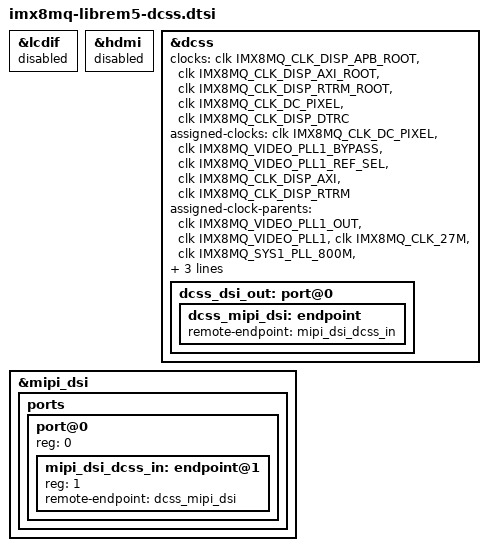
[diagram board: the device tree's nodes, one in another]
// SPDX-License-Identifier: GPL-2.0+
/*
 * Copyright 2021 Purism SPC
 */

/delete-node/ &mipi_dsi_lcdif_in;
/delete-node/ &lcdif_mipi_dsi;

&lcdif {
	status = "disabled";
};

&hdmi {
	status = "disabled";
};

&dcss {
	status = "okay";

	clocks = <&clk IMX8MQ_CLK_DISP_APB_ROOT>,
		 <&clk IMX8MQ_CLK_DISP_AXI_ROOT>,
		 <&clk IMX8MQ_CLK_DISP_RTRM_ROOT>,
		 <&clk IMX8MQ_CLK_DC_PIXEL>,
		 <&clk IMX8MQ_CLK_DISP_DTRC>;
	clock-names = "apb", "axi", "rtrm", "pix", "dtrc";
	assigned-clocks = <&clk IMX8MQ_CLK_DC_PIXEL>,
					  <&clk IMX8MQ_VIDEO_PLL1_BYPASS>,
					  <&clk IMX8MQ_VIDEO_PLL1_REF_SEL>,
					  <&clk IMX8MQ_CLK_DISP_AXI>,
					  <&clk IMX8MQ_CLK_DISP_RTRM>;
	assigned-clock-parents = <&clk IMX8MQ_VIDEO_PLL1_OUT>,
							 <&clk IMX8MQ_VIDEO_PLL1>,
							 <&clk IMX8MQ_CLK_27M>,
							 <&clk IMX8MQ_SYS1_PLL_800M>,
							 <&clk IMX8MQ_SYS1_PLL_800M>;
	assigned-clock-rates = <600000000>, <0>, <0>,
						   <800000000>,
						   <400000000>;
	dcss_dsi_out: port@0 {
		dcss_mipi_dsi: endpoint {
			remote-endpoint = <&mipi_dsi_dcss_in>;
		};
	};
};

&mipi_dsi {
	ports {
		#address-cells = <1>;
		#size-cells = <0>;

		port@0 {
			reg = <0>;
			#address-cells = <1>;
			#size-cells = <0>;

			mipi_dsi_dcss_in: endpoint@1 {
				reg = <1>;
				remote-endpoint = <&dcss_mipi_dsi>;
			};
		};

	};
};
